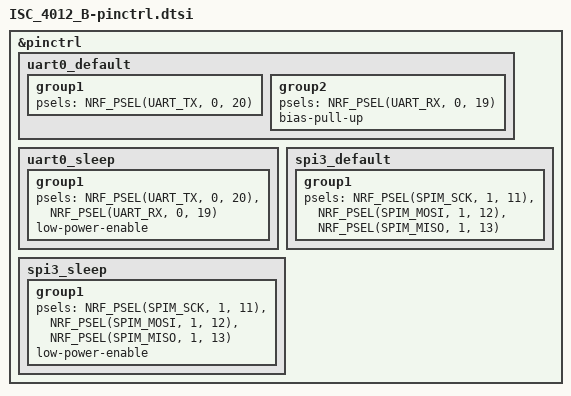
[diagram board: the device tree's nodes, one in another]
&pinctrl {
    uart0_default: uart0_default {
		group1 {
			psels = <NRF_PSEL(UART_TX, 0, 20)>;
		};
		group2 {
			psels = <NRF_PSEL(UART_RX, 0, 19)>;
			bias-pull-up;
		};
	};

	uart0_sleep: uart0_sleep {
		group1 {
			psels = <NRF_PSEL(UART_TX, 0, 20)>,
				<NRF_PSEL(UART_RX, 0, 19)>;
			low-power-enable;
		};
	};

    spi3_default: spi3_default {
        group1 {
            psels = <NRF_PSEL(SPIM_SCK, 1, 11)>,
                <NRF_PSEL(SPIM_MOSI, 1, 12)>,
                <NRF_PSEL(SPIM_MISO, 1, 13)>;
        };
    };

    spi3_sleep: spi3_sleep {
        group1 {
            psels = <NRF_PSEL(SPIM_SCK, 1, 11)>,
                <NRF_PSEL(SPIM_MOSI, 1, 12)>,
                <NRF_PSEL(SPIM_MISO, 1, 13)>;
            low-power-enable;
        };
    };
};
